# STM32G554 register map
File version: 2.0.0
CPU: CM33 r0p4, little endian, MPU, FPU, 4 interrupt priority bits
Registers are 32-bit, read-write, reset 0x0 unless marked. A register's access mark holds for its fields unless they carry their own. Offsets are from the block's base; [hi:lo] are bit positions; {n}, {i} and the like mark numbered series.

## CORDIC1 — CORDIC register block
Base 0x40023800
Same registers: CORDIC1_S 0x50023800
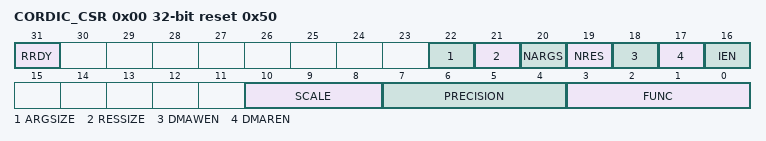
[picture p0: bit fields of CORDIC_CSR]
0x00 CORDIC_CSR reset 0x50 — CORDIC control/status register
  [31] RRDY ro — Result ready flag
    0=No new data in output register; 1=CORDIC_RDATA register contains new data
  [22] ARGSIZE — Width of input data
    0=32-bit; 1=16-bit
  [21] RESSIZE — Width of output data
    0=32-bit; 1=16-bit
  [20] NARGS — Number of arguments expected by the CORDIC_WDATA register
    0=Only one 32-bit write (or two 16-bit values if ARGSIZE = 1) is needed for the next calculation; 1=Two 32-bit values must be written to the CORDIC_WDATA register to trigger the next calculation
  [19] NRES — Number of results in the CORDIC_RDATA register
    0=Only one 32-bit value (or two 16-bit values if RESSIZE = 1) is transferred to the CORDIC_RDATA register on completion of the next calculation. One read from CORDIC_RDATA resets the RRDY flag.; 1=Two 32-bit values are transferred to the CORDIC_RDATA register on completion of the next calculation. Two reads from CORDIC_RDATA are necessary to reset the RRDY flag.
  [18] DMAWEN — Enable DMA write channel
    0=Disabled. No DMA write requests are generated.; 1=Enabled. Requests are generated on the DMA write channel whenever no operation is pending
  [17] DMAREN — Enable DMA read channel
    0=Disabled. No DMA read requests are generated.; 1=Enabled. Requests are generated on the DMA read channel whenever the RRDY flag is set.
  [16] IEN — Enable interrupt.
    0=Disabled. No interrupt requests are generated.; 1=Enabled. An interrupt request is generated whenever the RRDY flag is set.
  [10:8] SCALE — Scaling factor
  [7:4] PRECISION — Precision required (number of iterations)
  [3:0] FUNC — Function
    0=Cosine; 1=Sine
0x04 CORDIC_WDATA wo reset not defined — CORDIC argument register
  [31:0] ARG — Function input arguments
0x08 CORDIC_RDATA ro — CORDIC result register
  [31:0] RES — Function result

## CRC — CRC address block description
Base 0x40023000
Same registers: CRC_S 0x50023000
0x00 CRC_DR reset 0xFFFFFFFF — CRC data register
  [31:0] DR — Data register bits
0x04 CRC_IDR — CRC independent data register
  [31:0] IDR — General-purpose 32-bit data register bits
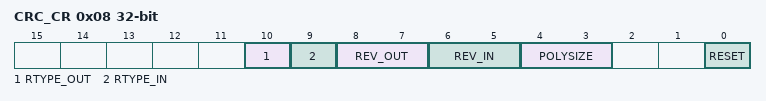
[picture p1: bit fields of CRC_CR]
0x08 CRC_CR — CRC control register
  [10] RTYPE_OUT — Reverse type output
    0=Bit level output; 1=Byte or half-word level output
  [9] RTYPE_IN — Reverse type input
    0=Bit level input; 1=Byte or half-word level input
  [8:7] REV_OUT — Reverse output data
    0=Bit order not affected (RTYPE_OUT=0 or 1); 1=Bit-reversed output format (RTYPE_OUT=0) or half-word reversal done by word (RTYPE_OUT=1); 2=Bit order not affected (RTYPE_OUT=0) or byte reversal done by word (RTYPE_OUT=1); 3=Bit order not affected (RTYPE_OUT=0 or 1)
  [6:5] REV_IN — Reverse input data
    0=Bit order not affected (RTYPE_IN=0 or 1); 1=Bit reversal done by byte (RTYPE_IN=0) or half-word reversal done by word (RTYPE_IN=1); 2=Bit reversal done by half-word (RTYPE_IN=0) or byte reversal done by word (RTYPE_IN=1); 3=Bit reversal done by word (RTYPE_IN=0) or bit order is not affected (RTYPE_IN=1)
  [4:3] POLYSIZE — Polynomial size
    0=32 bit polynomial; 1=16 bit polynomial; 2=8 bit polynomial; 3=7 bit polynomial
  [0] RESET — RESET bit
0x10 CRC_INIT reset 0xFFFFFFFF — CRC initial value
  [31:0] CRC_INIT — Programmable initial CRC value
0x14 CRC_POL reset 0x4C11DB7 — CRC polynomial
  [31:0] POL — Programmable polynomial

## CRS — CRS address block description
Base 0x40006000
Same registers: CRS_S 0x50006000
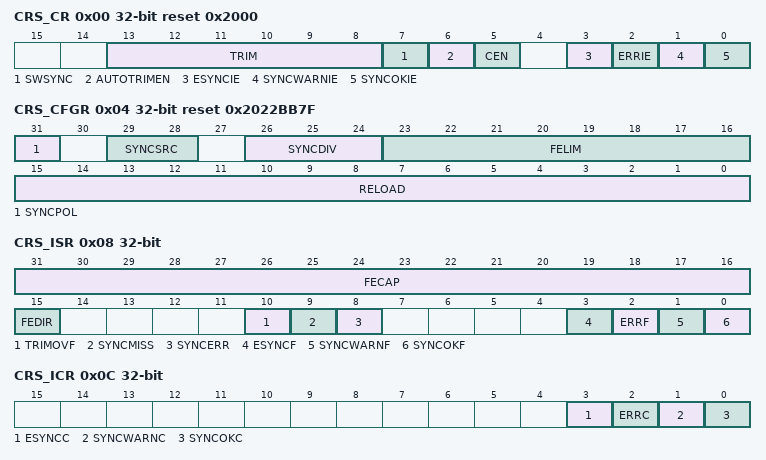
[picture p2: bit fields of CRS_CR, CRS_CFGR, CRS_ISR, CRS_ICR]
0x00 CRS_CR reset 0x2000 — CRS control register
  [13:8] TRIM — HSI48 oscillator smooth trimming
  [7] SWSYNC — Generate software SYNC event
    0=No action; 1=A software SYNC event is generated
  [6] AUTOTRIMEN — Automatic trimming enable
    0=Automatic trimming disabled, TRIM bits can be adjusted by the user; 1=Automatic trimming enabled, TRIM bits are read-only and under hardware control
  [5] CEN — Frequency error counter enable
    0=Frequency error counter disabled; 1=Frequency error counter enabled
  [3] ESYNCIE — Expected SYNC interrupt enable
    0=Expected SYNC (ESYNCF) interrupt disabled; 1=Expected SYNC (ESYNCF) interrupt enabled
  [2] ERRIE — Synchronization or trimming error interrupt enable
    0=Synchronization or trimming error (ERRF) interrupt disabled; 1=Synchronization or trimming error (ERRF) interrupt enabled
  [1] SYNCWARNIE — SYNC warning interrupt enable
    0=SYNC warning (SYNCWARNF) interrupt disabled; 1=SYNC warning (SYNCWARNF) interrupt enabled
  [0] SYNCOKIE — SYNC event OK interrupt enable
    0=SYNC event OK (SYNCOKF) interrupt disabled; 1=SYNC event OK (SYNCOKF) interrupt enabled
0x04 CRS_CFGR reset 0x2022BB7F — CRS configuration register
  [31] SYNCPOL — SYNC polarity selection
    0=SYNC active on rising edge (default); 1=SYNC active on falling edge
  [29:28] SYNCSRC — SYNC signal source selection
    {v}=crs_sync_in_{v+1} selected as SYNC signal source (v=0..3)
  [26:24] SYNCDIV — SYNC divider
    0=SYNC not divided (default); 1=SYNC divided by 2; 2=SYNC divided by 4; 3=SYNC divided by 8; 4=SYNC divided by 16; 5=SYNC divided by 32; 6=SYNC divided by 64; 7=SYNC divided by 128
  [23:16] FELIM — Frequency error limit
  [15:0] RELOAD — Counter reload value
0x08 CRS_ISR ro — CRS interrupt and status register
  [31:16] FECAP — Frequency error capture
  [15] FEDIR — Frequency error direction
    0=Up-counting direction, the actual frequency is above the target; 1=Down-counting direction, the actual frequency is below the target
  [10] TRIMOVF — Trimming overflow or underflow
    0=No trimming error signaled; 1=Trimming error signaled
  [9] SYNCMISS — SYNC missed
    0=No SYNC missed error signaled; 1=SYNC missed error signaled
  [8] SYNCERR — SYNC error
    0=No SYNC error signaled; 1=SYNC error signaled
  [3] ESYNCF — Expected SYNC flag
    0=No expected SYNC signaled; 1=Expected SYNC signaled
  [2] ERRF — Error flag
    0=No synchronization or trimming error signaled; 1=Synchronization or trimming error signaled
  [1] SYNCWARNF — SYNC warning flag
    0=No SYNC warning signaled; 1=SYNC warning signaled
  [0] SYNCOKF — SYNC event OK flag
    0=No SYNC event OK signaled; 1=SYNC event OK signaled
0x0C CRS_ICR — CRS interrupt flag clear register
  [3] ESYNCC — Expected SYNC clear flag
  [2] ERRC — Error clear flag
  [1] SYNCWARNC — SYNC warning clear flag
  [0] SYNCOKC — SYNC event OK clear flag

## Notices in the file
Copyright (c) 2026 STMicroelectronics.
SPDX-License-Identifier: Apache-2.0
Licensed under the Apache License, Version 2.0 (the "License");
you may not use this file except in compliance with the License.
You may obtain a copy of the License at
http://www.apache.org/licenses/LICENSE-2.0
Unless required by applicable law or agreed to in writing, software
distributed under the License is distributed on an "AS IS" BASIS,
WITHOUT WARRANTIES OR CONDITIONS OF ANY KIND, either express or implied.
See the License for the specific language governing permissions and
limitations under the License.
